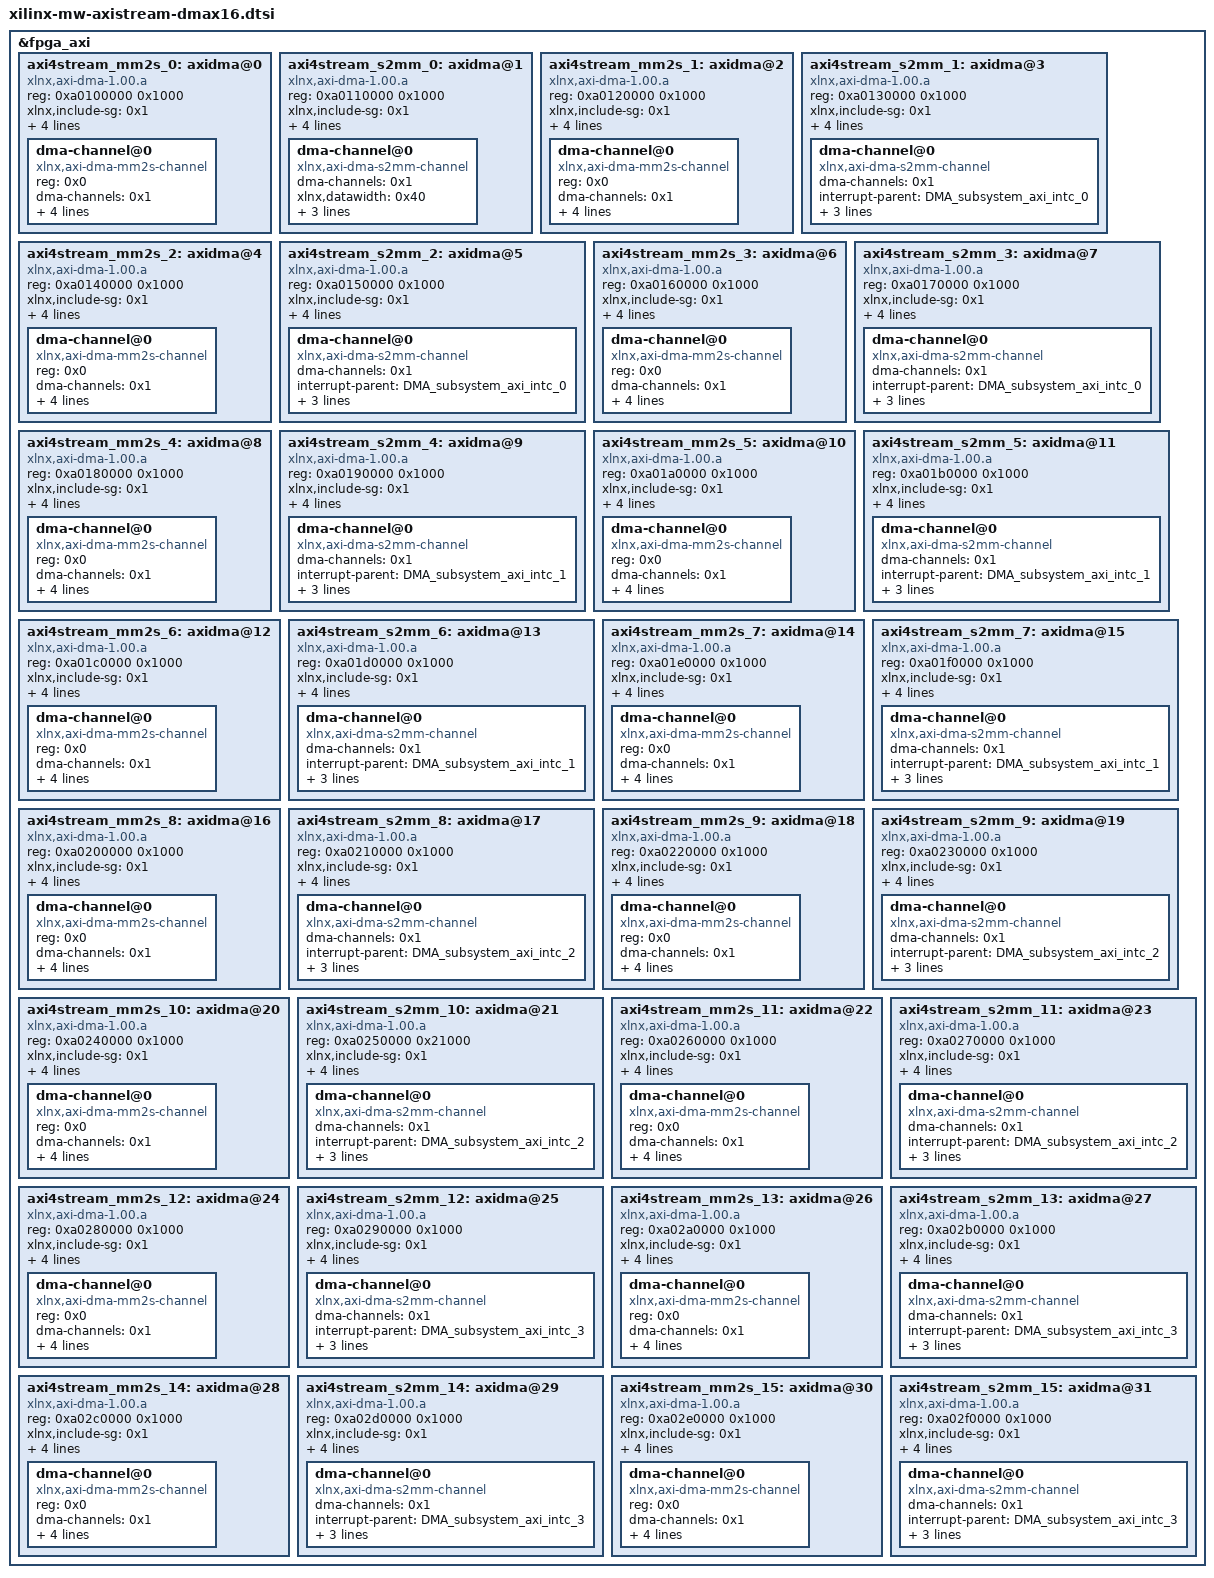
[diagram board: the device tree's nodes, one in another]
&fpga_axi {
	axi4stream_mm2s_0:axidma@0 {
		#dma-cells = <0x1>;
		#address-cells = <1>;
		#size-cells = <0>;
		compatible = "xlnx,axi-dma-1.00.a";
		reg = <0xa0100000 0x1000>;
		xlnx,include-sg = <0x1>;
		xlnx,halt-mode = "reset-always";
		xlnx,addrwidth = <0x20>;
		clocks = <&core_clkwiz 0>, <&core_clkwiz 0>, <&core_clkwiz 0>;
		clock-names = "s_axi_lite_aclk", "m_axi_sg_aclk", "m_axi_mm2s_aclk";
		dma-channel@0  {
			reg = <0x0>;
			compatible = "xlnx,axi-dma-mm2s-channel";
			dma-channels = <0x1>;
                        interrupt-parent = <&DMA_subsystem_axi_intc_0>;
                        interrupts = <1 2>;
			xlnx,datawidth = <0x40>;
			xlnx,device-id = <0x0>;
		};
	};
	axi4stream_s2mm_0:axidma@1 {
		#dma-cells = <0x1>;
		#address-cells = <1>;
		#size-cells = <0>;
		compatible = "xlnx,axi-dma-1.00.a";
		reg = <0xa0110000 0x1000>;
		xlnx,include-sg = <0x1>;
		xlnx,halt-mode = "reset-always";
		xlnx,addrwidth = <0x20>;
		clocks = <&core_clkwiz 0>, <&core_clkwiz 0>, <&core_clkwiz 0>;
		clock-names = "s_axi_lite_aclk", "m_axi_sg_aclk", "m_axi_s2mm_aclk";
		dma-channel@0 {
			compatible = "xlnx,axi-dma-s2mm-channel";
			dma-channels = <0x1>;			
			xlnx,datawidth = <0x40>;
			xlnx,device-id = <0x1>;
                        interrupt-parent = <&DMA_subsystem_axi_intc_0>;
                        interrupts = <0 2>;
		};
	};
	axi4stream_mm2s_1:axidma@2 {
		#dma-cells = <0x1>;
		#address-cells = <1>;
		#size-cells = <0>;
		compatible = "xlnx,axi-dma-1.00.a";
		reg = <0xa0120000 0x1000>;
		xlnx,include-sg = <0x1>;
		xlnx,halt-mode = "reset-always";
		xlnx,addrwidth = <0x20>;
		clocks = <&core_clkwiz 0>, <&core_clkwiz 0>, <&core_clkwiz 0>;
		clock-names = "s_axi_lite_aclk", "m_axi_sg_aclk", "m_axi_mm2s_aclk";
		dma-channel@0  {
			reg = <0x0>;
			compatible = "xlnx,axi-dma-mm2s-channel";
			dma-channels = <0x1>;
                        interrupt-parent = <&DMA_subsystem_axi_intc_0>;
                        interrupts = <3 2>;
			xlnx,datawidth = <0x40>;
			xlnx,device-id = <0x2>;
		};
	};
	axi4stream_s2mm_1:axidma@3 {
		#dma-cells = <0x1>;
		#address-cells = <1>;
		#size-cells = <0>;
		compatible = "xlnx,axi-dma-1.00.a";
		reg = <0xa0130000 0x1000>;
		xlnx,include-sg = <0x1>;
		xlnx,halt-mode = "reset-always";
		xlnx,addrwidth = <0x20>;
		clocks = <&core_clkwiz 0>, <&core_clkwiz 0>, <&core_clkwiz 0>;
		clock-names = "s_axi_lite_aclk", "m_axi_sg_aclk", "m_axi_s2mm_aclk";
		dma-channel@0 {
			compatible = "xlnx,axi-dma-s2mm-channel";
			dma-channels = <0x1>;			
                        interrupt-parent = <&DMA_subsystem_axi_intc_0>;
                        interrupts = <2 2>;
			xlnx,datawidth = <0x40>;
			xlnx,device-id = <0x3>;
		};
	};
	axi4stream_mm2s_2:axidma@4 {
		#dma-cells = <0x1>;
		#address-cells = <1>;
		#size-cells = <0>;
		compatible = "xlnx,axi-dma-1.00.a";
		reg = <0xa0140000 0x1000>;
		xlnx,include-sg = <0x1>;
		xlnx,halt-mode = "reset-always";
		xlnx,addrwidth = <0x20>;
		clocks = <&core_clkwiz 0>, <&core_clkwiz 0>, <&core_clkwiz 0>;
		clock-names = "s_axi_lite_aclk", "m_axi_sg_aclk", "m_axi_mm2s_aclk";
		dma-channel@0  {
			reg = <0x0>;
			compatible = "xlnx,axi-dma-mm2s-channel";
			dma-channels = <0x1>;
                        interrupt-parent = <&DMA_subsystem_axi_intc_0>;
                        interrupts = <5 2>;
			xlnx,datawidth = <0x40>;
			xlnx,device-id = <0x4>;
		};
	};
	axi4stream_s2mm_2:axidma@5 {
		#dma-cells = <0x1>;
		#address-cells = <1>;
		#size-cells = <0>;
		compatible = "xlnx,axi-dma-1.00.a";
		reg = <0xa0150000 0x1000>;
		xlnx,include-sg = <0x1>;
		xlnx,halt-mode = "reset-always";
		xlnx,addrwidth = <0x20>;
		clocks = <&core_clkwiz 0>, <&core_clkwiz 0>, <&core_clkwiz 0>;
		clock-names = "s_axi_lite_aclk", "m_axi_sg_aclk", "m_axi_s2mm_aclk";
		dma-channel@0 {
			compatible = "xlnx,axi-dma-s2mm-channel";
			dma-channels = <0x1>;			
                        interrupt-parent = <&DMA_subsystem_axi_intc_0>;
                        interrupts = <4 2>;
			xlnx,datawidth = <0x40>;
			xlnx,device-id = <0x5>;
		};
	};
	axi4stream_mm2s_3:axidma@6 {
		#dma-cells = <0x1>;
		#address-cells = <1>;
		#size-cells = <0>;
		compatible = "xlnx,axi-dma-1.00.a";
		reg = <0xa0160000 0x1000>;
		xlnx,include-sg = <0x1>;
		xlnx,halt-mode = "reset-always";
		xlnx,addrwidth = <0x20>;
		clocks = <&core_clkwiz 0>, <&core_clkwiz 0>, <&core_clkwiz 0>;
		clock-names = "s_axi_lite_aclk", "m_axi_sg_aclk", "m_axi_mm2s_aclk";
		dma-channel@0  {
			reg = <0x0>;
			compatible = "xlnx,axi-dma-mm2s-channel";
			dma-channels = <0x1>;
                        interrupt-parent = <&DMA_subsystem_axi_intc_0>;
                        interrupts = <7 2>;
			xlnx,datawidth = <0x40>;
			xlnx,device-id = <0x6>;
		};
	};
	axi4stream_s2mm_3:axidma@7 {
		#dma-cells = <0x1>;
		#address-cells = <1>;
		#size-cells = <0>;
		compatible = "xlnx,axi-dma-1.00.a";
		reg = <0xa0170000 0x1000>;
		xlnx,include-sg = <0x1>;
		xlnx,halt-mode = "reset-always";
		xlnx,addrwidth = <0x20>;
		clocks = <&core_clkwiz 0>, <&core_clkwiz 0>, <&core_clkwiz 0>;
		clock-names = "s_axi_lite_aclk", "m_axi_sg_aclk", "m_axi_s2mm_aclk";
		dma-channel@0 {
			compatible = "xlnx,axi-dma-s2mm-channel";
			dma-channels = <0x1>;			
                        interrupt-parent = <&DMA_subsystem_axi_intc_0>;
                        interrupts = <6 2>;
			xlnx,datawidth = <0x40>;
			xlnx,device-id = <0x7>;
		};
	};
	axi4stream_mm2s_4:axidma@8 {
		#dma-cells = <0x1>;
		#address-cells = <1>;
		#size-cells = <0>;
		compatible = "xlnx,axi-dma-1.00.a";
		reg = <0xa0180000 0x1000>;
		xlnx,include-sg = <0x1>;
		xlnx,halt-mode = "reset-always";
		xlnx,addrwidth = <0x20>;
		clocks = <&core_clkwiz 0>, <&core_clkwiz 0>, <&core_clkwiz 0>;
		clock-names = "s_axi_lite_aclk", "m_axi_sg_aclk", "m_axi_mm2s_aclk";
		dma-channel@0  {
			reg = <0x0>;
			compatible = "xlnx,axi-dma-mm2s-channel";
			dma-channels = <0x1>;
                        interrupt-parent = <&DMA_subsystem_axi_intc_1>;
                        interrupts = <1 2>;
			xlnx,datawidth = <0x40>;
			xlnx,device-id = <0x8>;
		};
	};
	axi4stream_s2mm_4:axidma@9 {
		#dma-cells = <0x1>;
		#address-cells = <1>;
		#size-cells = <0>;
		compatible = "xlnx,axi-dma-1.00.a";
		reg = <0xa0190000 0x1000>;
		xlnx,include-sg = <0x1>;
		xlnx,halt-mode = "reset-always";
		xlnx,addrwidth = <0x20>;
		clocks = <&core_clkwiz 0>, <&core_clkwiz 0>, <&core_clkwiz 0>;
		clock-names = "s_axi_lite_aclk", "m_axi_sg_aclk", "m_axi_s2mm_aclk";
		dma-channel@0 {
			compatible = "xlnx,axi-dma-s2mm-channel";
			dma-channels = <0x1>;			
                        interrupt-parent = <&DMA_subsystem_axi_intc_1>;
                        interrupts = <0 2>;
			xlnx,datawidth = <0x40>;
			xlnx,device-id = <0x9>;
		};
	};
	axi4stream_mm2s_5:axidma@10 {
		#dma-cells = <0x1>;
		#address-cells = <1>;
		#size-cells = <0>;
		compatible = "xlnx,axi-dma-1.00.a";
		reg = <0xa01a0000 0x1000>;
		xlnx,include-sg = <0x1>;
		xlnx,halt-mode = "reset-always";
		xlnx,addrwidth = <0x20>;
		clocks = <&core_clkwiz 0>, <&core_clkwiz 0>, <&core_clkwiz 0>;
		clock-names = "s_axi_lite_aclk", "m_axi_sg_aclk", "m_axi_mm2s_aclk";
		dma-channel@0  {
			reg = <0x0>;
			compatible = "xlnx,axi-dma-mm2s-channel";
			dma-channels = <0x1>;
                        interrupt-parent = <&DMA_subsystem_axi_intc_1>;
                        interrupts = <3 2>;
			xlnx,datawidth = <0x40>;
			xlnx,device-id = <0xa>;
		};
	};
	axi4stream_s2mm_5:axidma@11 {
		#dma-cells = <0x1>;
		#address-cells = <1>;
		#size-cells = <0>;
		compatible = "xlnx,axi-dma-1.00.a";
		reg = <0xa01b0000 0x1000>;
		xlnx,include-sg = <0x1>;
		xlnx,halt-mode = "reset-always";
		xlnx,addrwidth = <0x20>;
		clocks = <&core_clkwiz 0>, <&core_clkwiz 0>, <&core_clkwiz 0>;
		clock-names = "s_axi_lite_aclk", "m_axi_sg_aclk", "m_axi_s2mm_aclk";
		dma-channel@0 {
			compatible = "xlnx,axi-dma-s2mm-channel";
			dma-channels = <0x1>;			
                        interrupt-parent = <&DMA_subsystem_axi_intc_1>;
                        interrupts = <2 2>;
			xlnx,datawidth = <0x40>;
			xlnx,device-id = <0xb>;
		};
	};
	axi4stream_mm2s_6:axidma@12 {
		#dma-cells = <0x1>;
		#address-cells = <1>;
		#size-cells = <0>;
		compatible = "xlnx,axi-dma-1.00.a";
		reg = <0xa01c0000 0x1000>;
		xlnx,include-sg = <0x1>;
		xlnx,halt-mode = "reset-always";
		xlnx,addrwidth = <0x20>;
		clocks = <&core_clkwiz 0>, <&core_clkwiz 0>, <&core_clkwiz 0>;
		clock-names = "s_axi_lite_aclk", "m_axi_sg_aclk", "m_axi_mm2s_aclk";
		dma-channel@0  {
			reg = <0x0>;
			compatible = "xlnx,axi-dma-mm2s-channel";
			dma-channels = <0x1>;
                        interrupt-parent = <&DMA_subsystem_axi_intc_1>;
                        interrupts = <5 2>;
			xlnx,datawidth = <0x40>;
			xlnx,device-id = <0xc>;
		};
	};
	axi4stream_s2mm_6:axidma@13 {
		#dma-cells = <0x1>;
		#address-cells = <1>;
		#size-cells = <0>;
		compatible = "xlnx,axi-dma-1.00.a";
		reg = <0xa01d0000 0x1000>;
		xlnx,include-sg = <0x1>;
		xlnx,halt-mode = "reset-always";
		xlnx,addrwidth = <0x20>;
		clocks = <&core_clkwiz 0>, <&core_clkwiz 0>, <&core_clkwiz 0>;
		clock-names = "s_axi_lite_aclk", "m_axi_sg_aclk", "m_axi_s2mm_aclk";
		dma-channel@0 {
			compatible = "xlnx,axi-dma-s2mm-channel";
			dma-channels = <0x1>;			
                        interrupt-parent = <&DMA_subsystem_axi_intc_1>;
                        interrupts = <4 2>;
			xlnx,datawidth = <0x40>;
			xlnx,device-id = <0xd>;
		};
	};
	axi4stream_mm2s_7:axidma@14 {
		#dma-cells = <0x1>;
		#address-cells = <1>;
		#size-cells = <0>;
		compatible = "xlnx,axi-dma-1.00.a";
		reg = <0xa01e0000 0x1000>;
		xlnx,include-sg = <0x1>;
		xlnx,halt-mode = "reset-always";
		xlnx,addrwidth = <0x20>;
		clocks = <&core_clkwiz 0>, <&core_clkwiz 0>, <&core_clkwiz 0>;
		clock-names = "s_axi_lite_aclk", "m_axi_sg_aclk", "m_axi_mm2s_aclk";
		dma-channel@0  {
			reg = <0x0>;
			compatible = "xlnx,axi-dma-mm2s-channel";
			dma-channels = <0x1>;
                        interrupt-parent = <&DMA_subsystem_axi_intc_1>;
                        interrupts = <7 2>;
			xlnx,datawidth = <0x40>;
			xlnx,device-id = <0xe>;
		};
	};
	axi4stream_s2mm_7:axidma@15 {
		#dma-cells = <0x1>;
		#address-cells = <1>;
		#size-cells = <0>;
		compatible = "xlnx,axi-dma-1.00.a";
		reg = <0xa01f0000 0x1000>;
		xlnx,include-sg = <0x1>;
		xlnx,halt-mode = "reset-always";
		xlnx,addrwidth = <0x20>;
		clocks = <&core_clkwiz 0>, <&core_clkwiz 0>, <&core_clkwiz 0>;
		clock-names = "s_axi_lite_aclk", "m_axi_sg_aclk", "m_axi_s2mm_aclk";
		dma-channel@0 {
			compatible = "xlnx,axi-dma-s2mm-channel";
			dma-channels = <0x1>;			
                        interrupt-parent = <&DMA_subsystem_axi_intc_1>;
                        interrupts = <6 2>;
			xlnx,datawidth = <0x40>;
			xlnx,device-id = <0xf>;
		};
	};
	axi4stream_mm2s_8:axidma@16 {
		#dma-cells = <0x1>;
		#address-cells = <1>;
		#size-cells = <0>;
		compatible = "xlnx,axi-dma-1.00.a";
		reg = <0xa0200000 0x1000>;
		xlnx,include-sg = <0x1>;
		xlnx,halt-mode = "reset-always";
		xlnx,addrwidth = <0x20>;
		clocks = <&core_clkwiz 0>, <&core_clkwiz 0>, <&core_clkwiz 0>;
		clock-names = "s_axi_lite_aclk", "m_axi_sg_aclk", "m_axi_mm2s_aclk";
		dma-channel@0  {
			reg = <0x0>;
			compatible = "xlnx,axi-dma-mm2s-channel";
			dma-channels = <0x1>;
                        interrupt-parent = <&DMA_subsystem_axi_intc_2>;
                        interrupts = <1 2>;
			xlnx,datawidth = <0x40>;
			xlnx,device-id = <0x10>;
		};
	};
	axi4stream_s2mm_8:axidma@17 {
		#dma-cells = <0x1>;
		#address-cells = <1>;
		#size-cells = <0>;
		compatible = "xlnx,axi-dma-1.00.a";
		reg = <0xa0210000 0x1000>;
		xlnx,include-sg = <0x1>;
		xlnx,halt-mode = "reset-always";
		xlnx,addrwidth = <0x20>;
		clocks = <&core_clkwiz 0>, <&core_clkwiz 0>, <&core_clkwiz 0>;
		clock-names = "s_axi_lite_aclk", "m_axi_sg_aclk", "m_axi_s2mm_aclk";
		dma-channel@0 {
			compatible = "xlnx,axi-dma-s2mm-channel";
			dma-channels = <0x1>;			
                        interrupt-parent = <&DMA_subsystem_axi_intc_2>;
                        interrupts = <0 2>;
			xlnx,datawidth = <0x40>;
			xlnx,device-id = <0x11>;
		};
	};
	axi4stream_mm2s_9:axidma@18 {
		#dma-cells = <0x1>;
		#address-cells = <1>;
		#size-cells = <0>;
		compatible = "xlnx,axi-dma-1.00.a";
		reg = <0xa0220000 0x1000>;
		xlnx,include-sg = <0x1>;
		xlnx,halt-mode = "reset-always";
		xlnx,addrwidth = <0x20>;
		clocks = <&core_clkwiz 0>, <&core_clkwiz 0>, <&core_clkwiz 0>;
		clock-names = "s_axi_lite_aclk", "m_axi_sg_aclk", "m_axi_mm2s_aclk";
		dma-channel@0  {
			reg = <0x0>;
			compatible = "xlnx,axi-dma-mm2s-channel";
			dma-channels = <0x1>;
                        interrupt-parent = <&DMA_subsystem_axi_intc_2>;
                        interrupts = <3 2>;
			xlnx,datawidth = <0x40>;
			xlnx,device-id = <0x12>;
		};
	};
	axi4stream_s2mm_9:axidma@19 {
		#dma-cells = <0x1>;
		#address-cells = <1>;
		#size-cells = <0>;
		compatible = "xlnx,axi-dma-1.00.a";
		reg = <0xa0230000 0x1000>;
		xlnx,include-sg = <0x1>;
		xlnx,halt-mode = "reset-always";
		xlnx,addrwidth = <0x20>;
		clocks = <&core_clkwiz 0>, <&core_clkwiz 0>, <&core_clkwiz 0>;
		clock-names = "s_axi_lite_aclk", "m_axi_sg_aclk", "m_axi_s2mm_aclk";
		dma-channel@0 {
			compatible = "xlnx,axi-dma-s2mm-channel";
			dma-channels = <0x1>;			
                        interrupt-parent = <&DMA_subsystem_axi_intc_2>;
                        interrupts = <2 2>;
			xlnx,datawidth = <0x40>;
			xlnx,device-id = <0x13>;
		};
	};
	axi4stream_mm2s_10:axidma@20 {
		#dma-cells = <0x1>;
		#address-cells = <1>;
		#size-cells = <0>;
		compatible = "xlnx,axi-dma-1.00.a";
		reg = <0xa0240000 0x1000>;
		xlnx,include-sg = <0x1>;
		xlnx,halt-mode = "reset-always";
		xlnx,addrwidth = <0x20>;
		clocks = <&core_clkwiz 0>, <&core_clkwiz 0>, <&core_clkwiz 0>;
		clock-names = "s_axi_lite_aclk", "m_axi_sg_aclk", "m_axi_mm2s_aclk";
		dma-channel@0  {
			reg = <0x0>;
			compatible = "xlnx,axi-dma-mm2s-channel";
			dma-channels = <0x1>;
                        interrupt-parent = <&DMA_subsystem_axi_intc_2>;
                        interrupts = <5 2>;
			xlnx,datawidth = <0x40>;
			xlnx,device-id = <0x14>;
		};
	};
	axi4stream_s2mm_10:axidma@21 {
		#dma-cells = <0x1>;
		#address-cells = <1>;
		#size-cells = <0>;
		compatible = "xlnx,axi-dma-1.00.a";
		reg = <0xa0250000 0x21000>;
		xlnx,include-sg = <0x1>;
		xlnx,halt-mode = "reset-always";
		xlnx,addrwidth = <0x20>;
		clocks = <&core_clkwiz 0>, <&core_clkwiz 0>, <&core_clkwiz 0>;
		clock-names = "s_axi_lite_aclk", "m_axi_sg_aclk", "m_axi_s2mm_aclk";
		dma-channel@0 {
			compatible = "xlnx,axi-dma-s2mm-channel";
			dma-channels = <0x1>;			
                        interrupt-parent = <&DMA_subsystem_axi_intc_2>;
                        interrupts = <4 2>;
			xlnx,datawidth = <0x40>;
			xlnx,device-id = <0x15>;
		};
	};
	axi4stream_mm2s_11:axidma@22 {
		#dma-cells = <0x1>;
		#address-cells = <1>;
		#size-cells = <0>;
		compatible = "xlnx,axi-dma-1.00.a";
		reg = <0xa0260000 0x1000>;
		xlnx,include-sg = <0x1>;
		xlnx,halt-mode = "reset-always";
		xlnx,addrwidth = <0x20>;
		clocks = <&core_clkwiz 0>, <&core_clkwiz 0>, <&core_clkwiz 0>;
		clock-names = "s_axi_lite_aclk", "m_axi_sg_aclk", "m_axi_mm2s_aclk";
		dma-channel@0  {
			reg = <0x0>;
			compatible = "xlnx,axi-dma-mm2s-channel";
			dma-channels = <0x1>;
                        interrupt-parent = <&DMA_subsystem_axi_intc_2>;
                        interrupts = <7 2>;
			xlnx,datawidth = <0x40>;
			xlnx,device-id = <0x16>;
		};
	};
	axi4stream_s2mm_11:axidma@23 {
		#dma-cells = <0x1>;
		#address-cells = <1>;
		#size-cells = <0>;
		compatible = "xlnx,axi-dma-1.00.a";
		reg = <0xa0270000 0x1000>;
		xlnx,include-sg = <0x1>;
		xlnx,halt-mode = "reset-always";
		xlnx,addrwidth = <0x20>;
		clocks = <&core_clkwiz 0>, <&core_clkwiz 0>, <&core_clkwiz 0>;
		clock-names = "s_axi_lite_aclk", "m_axi_sg_aclk", "m_axi_s2mm_aclk";
		dma-channel@0 {
			compatible = "xlnx,axi-dma-s2mm-channel";
			dma-channels = <0x1>;			
                        interrupt-parent = <&DMA_subsystem_axi_intc_2>;
                        interrupts = <6 2>;
			xlnx,datawidth = <0x40>;
			xlnx,device-id = <0x17>;
		};
	};
	axi4stream_mm2s_12:axidma@24 {
		#dma-cells = <0x1>;
		#address-cells = <1>;
		#size-cells = <0>;
		compatible = "xlnx,axi-dma-1.00.a";
		reg = <0xa0280000 0x1000>;
		xlnx,include-sg = <0x1>;
		xlnx,halt-mode = "reset-always";
		xlnx,addrwidth = <0x20>;
		clocks = <&core_clkwiz 0>, <&core_clkwiz 0>, <&core_clkwiz 0>;
		clock-names = "s_axi_lite_aclk", "m_axi_sg_aclk", "m_axi_mm2s_aclk";
		dma-channel@0  {
			reg = <0x0>;
			compatible = "xlnx,axi-dma-mm2s-channel";
			dma-channels = <0x1>;
                        interrupt-parent = <&DMA_subsystem_axi_intc_3>;
                        interrupts = <1 2>;
			xlnx,datawidth = <0x40>;
			xlnx,device-id = <0x18>;
		};
	};
	axi4stream_s2mm_12:axidma@25 {
		#dma-cells = <0x1>;
		#address-cells = <1>;
		#size-cells = <0>;
		compatible = "xlnx,axi-dma-1.00.a";
		reg = <0xa0290000 0x1000>;
		xlnx,include-sg = <0x1>;
		xlnx,halt-mode = "reset-always";
		xlnx,addrwidth = <0x20>;
		clocks = <&core_clkwiz 0>, <&core_clkwiz 0>, <&core_clkwiz 0>;
		clock-names = "s_axi_lite_aclk", "m_axi_sg_aclk", "m_axi_s2mm_aclk";
		dma-channel@0 {
			compatible = "xlnx,axi-dma-s2mm-channel";
			dma-channels = <0x1>;			
                        interrupt-parent = <&DMA_subsystem_axi_intc_3>;
                        interrupts = <0 2>;
			xlnx,datawidth = <0x40>;
			xlnx,device-id = <0x19>;
		};
	};
	axi4stream_mm2s_13:axidma@26 {
		#dma-cells = <0x1>;
		#address-cells = <1>;
		#size-cells = <0>;
		compatible = "xlnx,axi-dma-1.00.a";
		reg = <0xa02a0000 0x1000>;
		xlnx,include-sg = <0x1>;
		xlnx,halt-mode = "reset-always";
		xlnx,addrwidth = <0x20>;
		clocks = <&core_clkwiz 0>, <&core_clkwiz 0>, <&core_clkwiz 0>;
		clock-names = "s_axi_lite_aclk", "m_axi_sg_aclk", "m_axi_mm2s_aclk";
		dma-channel@0  {
			reg = <0x0>;
			compatible = "xlnx,axi-dma-mm2s-channel";
			dma-channels = <0x1>;
                        interrupt-parent = <&DMA_subsystem_axi_intc_3>;
                        interrupts = <3 2>;
			xlnx,datawidth = <0x40>;
			xlnx,device-id = <0x1a>;
		};
	};
	axi4stream_s2mm_13:axidma@27 {
		#dma-cells = <0x1>;
		#address-cells = <1>;
		#size-cells = <0>;
		compatible = "xlnx,axi-dma-1.00.a";
		reg = <0xa02b0000 0x1000>;
		xlnx,include-sg = <0x1>;
		xlnx,halt-mode = "reset-always";
		xlnx,addrwidth = <0x20>;
		clocks = <&core_clkwiz 0>, <&core_clkwiz 0>, <&core_clkwiz 0>;
		clock-names = "s_axi_lite_aclk", "m_axi_sg_aclk", "m_axi_s2mm_aclk";
		dma-channel@0 {
			compatible = "xlnx,axi-dma-s2mm-channel";
			dma-channels = <0x1>;			
                        interrupt-parent = <&DMA_subsystem_axi_intc_3>;
                        interrupts = <2 2>;
			xlnx,datawidth = <0x40>;
			xlnx,device-id = <0x1b>;
		};
	};
	axi4stream_mm2s_14:axidma@28 {
		#dma-cells = <0x1>;
		#address-cells = <1>;
		#size-cells = <0>;
		compatible = "xlnx,axi-dma-1.00.a";
		reg = <0xa02c0000 0x1000>;
		xlnx,include-sg = <0x1>;
		xlnx,halt-mode = "reset-always";
		xlnx,addrwidth = <0x20>;
		clocks = <&core_clkwiz 0>, <&core_clkwiz 0>, <&core_clkwiz 0>;
		clock-names = "s_axi_lite_aclk", "m_axi_sg_aclk", "m_axi_mm2s_aclk";
		dma-channel@0  {
			reg = <0x0>;
			compatible = "xlnx,axi-dma-mm2s-channel";
			dma-channels = <0x1>;
                        interrupt-parent = <&DMA_subsystem_axi_intc_3>;
                        interrupts = <5 2>;
			xlnx,datawidth = <0x40>;
			xlnx,device-id = <0x1c>;
		};
	};
	axi4stream_s2mm_14:axidma@29 {
		#dma-cells = <0x1>;
		#address-cells = <1>;
		#size-cells = <0>;
		compatible = "xlnx,axi-dma-1.00.a";
		reg = <0xa02d0000 0x1000>;
		xlnx,include-sg = <0x1>;
		xlnx,halt-mode = "reset-always";
		xlnx,addrwidth = <0x20>;
		clocks = <&core_clkwiz 0>, <&core_clkwiz 0>, <&core_clkwiz 0>;
		clock-names = "s_axi_lite_aclk", "m_axi_sg_aclk", "m_axi_s2mm_aclk";
		dma-channel@0 {
			compatible = "xlnx,axi-dma-s2mm-channel";
			dma-channels = <0x1>;			
                        interrupt-parent = <&DMA_subsystem_axi_intc_3>;
                        interrupts = <4 2>;
			xlnx,datawidth = <0x40>;
			xlnx,device-id = <0x1d>;
		};
	};
	axi4stream_mm2s_15:axidma@30 {
		#dma-cells = <0x1>;
		#address-cells = <1>;
		#size-cells = <0>;
		compatible = "xlnx,axi-dma-1.00.a";
		reg = <0xa02e0000 0x1000>;
		xlnx,include-sg = <0x1>;
		xlnx,halt-mode = "reset-always";
		xlnx,addrwidth = <0x20>;
		clocks = <&core_clkwiz 0>, <&core_clkwiz 0>, <&core_clkwiz 0>;
		clock-names = "s_axi_lite_aclk", "m_axi_sg_aclk", "m_axi_mm2s_aclk";
		dma-channel@0  {
			reg = <0x0>;
			compatible = "xlnx,axi-dma-mm2s-channel";
			dma-channels = <0x1>;
                        interrupt-parent = <&DMA_subsystem_axi_intc_3>;
                        interrupts = <7 2>;
			xlnx,datawidth = <0x40>;
			xlnx,device-id = <0x1e>;
		};
	};
	axi4stream_s2mm_15:axidma@31 {
		#dma-cells = <0x1>;
		#address-cells = <1>;
		#size-cells = <0>;
		compatible = "xlnx,axi-dma-1.00.a";
		reg = <0xa02f0000 0x1000>;
		xlnx,include-sg = <0x1>;
		xlnx,halt-mode = "reset-always";
		xlnx,addrwidth = <0x20>;
		clocks = <&core_clkwiz 0>, <&core_clkwiz 0>, <&core_clkwiz 0>;
		clock-names = "s_axi_lite_aclk", "m_axi_sg_aclk", "m_axi_s2mm_aclk";
		dma-channel@0 {
			compatible = "xlnx,axi-dma-s2mm-channel";
			dma-channels = <0x1>;			
                        interrupt-parent = <&DMA_subsystem_axi_intc_3>;
                        interrupts = <6 2>;
			xlnx,datawidth = <0x40>;
			xlnx,device-id = <0x1f>;
		};
	};
};

